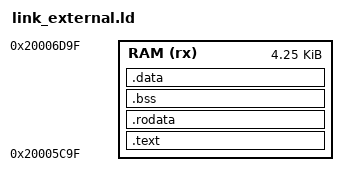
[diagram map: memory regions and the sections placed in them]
STARTADRESS = 0x20005c9f;
SIZE = 4353;

MEMORY
{
  RAM (rx) : ORIGIN = STARTADRESS, LENGTH = SIZE
}

ENTRY(main);

SECTIONS
{
  .text :
  {
    KEEP(*(.main))
    *(.text .text.*);
  } > RAM

  .rodata :
  {
    *(.rodata .rodata.*);
  } > RAM

  .bss :
  {
    _sbss = .;
    *(.bss .bss.*);
    _ebss = .;
  } > RAM

  .data :
  {
    _sdata = .;
    *(.data .data.*);
    _edata = .;
  } > RAM

  /DISCARD/ :
  {
    *(.ARM.exidx .ARM.exidx.*);
  }
}
